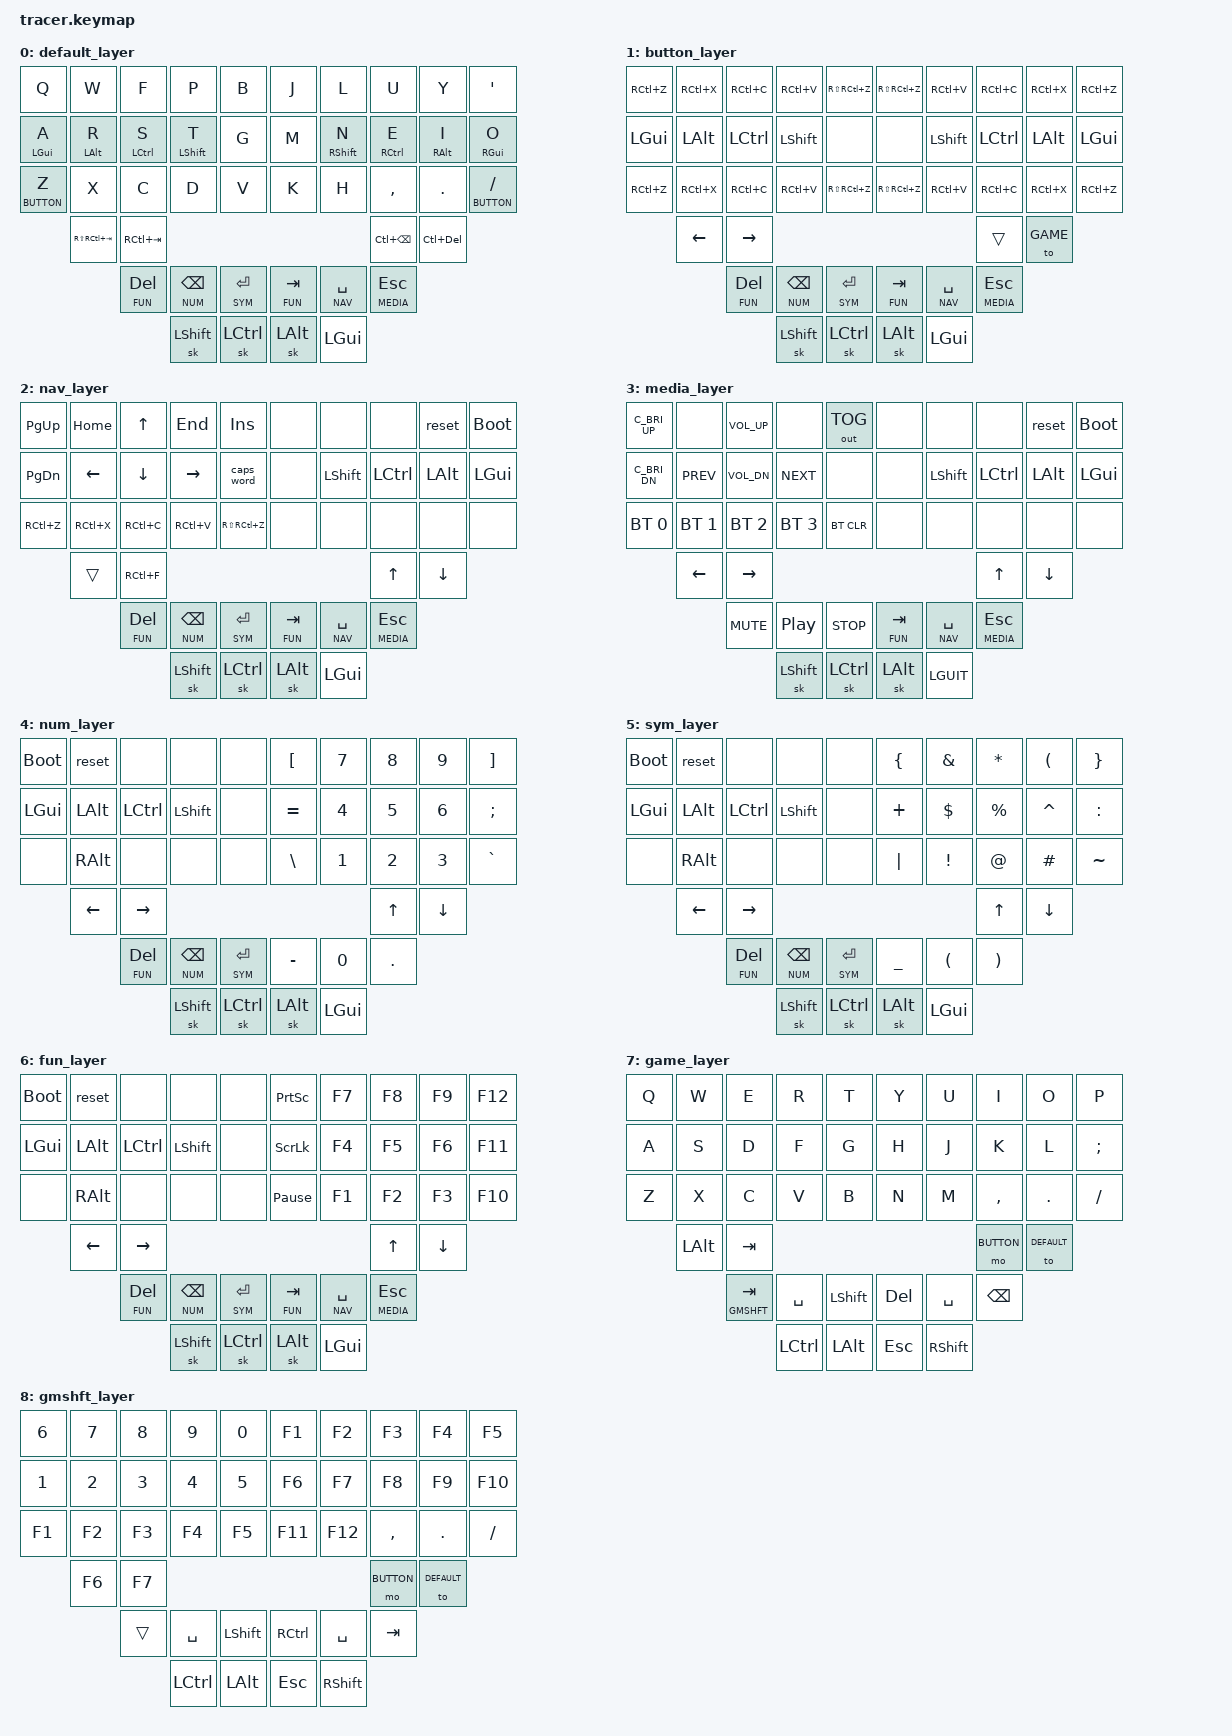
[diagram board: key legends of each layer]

#include <behaviors.dtsi>
#include <dt-bindings/zmk/keys.h>
#include <dt-bindings/zmk/bt.h>
#include <dt-bindings/zmk/outputs.h>

#define DEFAULT 0
#define BUTTON 1
#define NAV    2
#define MEDIA  3
#define NUM    4
#define SYM    5
#define FUN    6
#define GAME   7
#define GMSHFT 8

/ {
	behaviors {
        hm: homerow_mods {
            compatible = "zmk,behavior-hold-tap";
            label = "HOMEROW_MODS";
            #binding-cells = <2>;
            tapping-term-ms = <150>;
            quick-tap-ms = <0>;
            flavor = "tap-preferred";
            bindings = <&kp>,  <&kp>;
        };
    };
	keymap {
		compatible = "zmk,keymap";

		default_layer {
			bindings = <
				&kp Q		&kp W       &kp F         &kp P        &kp B				&kp J   &kp L        &kp U        &kp Y       &kp SQT
				&hm LGUI A	&hm LALT R  &hm LCTRL S   &hm LSHIFT T &kp G				&kp M   &hm RSHFT N  &hm RCTRL E  &hm RALT I  &hm RGUI O
				&lt BUTTON Z &kp X      &kp C         &kp D        &kp V				&kp K   &kp H        &kp COMMA    &kp DOT     &lt BUTTON SLASH
                            &kp RS(RC(TAB))    &kp RC(TAB)                                                   &kp LC(BSPC) &kp LC(DEL)
                                        &lt FUN DEL &lt NUM BSPC  &lt SYM RET           &lt FUN TAB &lt NAV SPACE  &lt MEDIA ESC
                                            	    &sk LSHFT &sk LCTRL 	            &sk LALT  &kp LGUI
			>;

		};

		button_layer {
			bindings = <
				&kp RC(Z)	&kp RC(X)	&kp RC(C)	&kp RC(V)	&kp RS(RC(Z))			&kp RS(RC(Z))	&kp RC(V)	&kp RC(C)	&kp RC(X)	&kp RC(Z)
				&kp LGUI	&kp LALT	&kp LCTRL   &kp LSHFT   &none           		&none      		&kp LSHFT   &kp LCTRL   &kp LALT    &kp LGUI	
				&kp RC(Z)	&kp RC(X)	&kp RC(C)	&kp RC(V)	&kp RS(RC(Z))			&kp RS(RC(Z))	&kp RC(V)	&kp RC(C)	&kp RC(X)	&kp RC(Z) 	 
					        &kp LEFT    &kp RIGHT                                                            &trans     &to GAME
                                        &lt FUN DEL &lt NUM BSPC  &lt SYM RET           &lt FUN TAB &lt NAV SPACE  &lt MEDIA ESC
                                            	    &sk LSHFT &sk LCTRL               &sk LALT  &kp LGUI
			>;    
		};

		nav_layer {
			bindings = <
				&kp PG_UP   &kp HOME      &kp UP        &kp END      &kp INS            &none   &none       &none       &reset		&bootloader
				&kp PG_DN   &kp LEFT      &kp DOWN      &kp RIGHT    &caps_word          &none   &kp LSHFT	&kp LCTRL   &kp LALT    &kp LGUI  
				&kp RC(Z)   &kp RC(X)     &kp RC(C)    &kp RC(V)  &kp RS(RC(Z))         &none   &none       &none       &none  	&none
							&trans       &kp RC(F)                                                        &kp UP      &kp DOWN
							               &lt FUN DEL &lt NUM BSPC  &lt SYM RET        &lt FUN TAB &lt NAV SPACE &lt MEDIA ESC
                                                       &sk LSHFT &sk LCTRL	        &sk LALT  &kp LGUI
																																				
			>;

		};

		media_layer {
			bindings = <
				C_BRI_UP	&none 		&kp C_VOL_UP	&none &out OUT_TOG		            &none		&none	    &none 		&reset		&bootloader	
				C_BRI_DN 	&kp C_PREV  &kp C_VOL_DN	&kp C_NEXT	&none       		    &none		&kp LSHFT	&kp LCTRL	&kp LALT	&kp LGUI
				&bt BT_SEL 0 &bt BT_SEL 1 &bt BT_SEL 2		&bt BT_SEL 3 &bt BT_CLR				&none		&none		&none		&none		&none
							 &kp LEFT    &kp RIGHT                                                          &kp UP       &kp DOWN              	
							            &kp C_MUTE &kp C_PP	&kp C_STOP         		&lt FUN TAB &lt NAV SPACE  &lt MEDIA ESC
										           &sk LSHFT &sk LCTRL		 		&sk LALT  &kp LGUIT
						
	            >;

		};

		num_layer {
			bindings = <
				&bootloader    &reset		&none		&none		&none              &kp LBKT          &kp N7         &kp N8         &kp N9         &kp RBKT
				&kp LGUI       &kp LALT		&kp LCTRL	&kp LSHFT	&none              &kp EQL           &kp N4         &kp N5         &kp N6         &kp SEMI
				&none          &kp RALT		&none   	&none		&none              &kp BSLH          &kp N1         &kp N2         &kp N3         &kp GRAVE  
							   &kp LEFT	 	&kp RIGHT																	&kp UP    	   &kp DOWN
                                			&lt FUN DEL &lt NUM BSPC  &lt SYM RET        &kp MINUS       &kp N0         &kp DOT
								   					    &sk LSHFT &sk LCTRL			     &sk LALT  &kp LGUI
	            >;

		};

        sym_layer {
			bindings = <
				&bootloader		&reset		&none		&none		&none				&kp LBRC		&kp AMPS		&kp ASTRK		&kp LPAR		&kp RBRC
				&kp LGUI		&kp LALT	&kp LCTRL	&kp LSHFT	&none               &kp PLUS		&kp DLLR		&kp PRCNT		&kp CARET		&kp COLON 
				&none			&kp RALT	&none		&none		&none               &kp PIPE		&kp EXCL		&kp AT			&kp HASH		&kp TILDE  
								&kp LEFT	&kp RIGHT																	&kp UP    	    &kp DOWN
                                			&lt FUN DEL &lt NUM BSPC  &lt SYM RET       		&kp UNDER		&kp LPAR		&kp RPAR
								   					    &sk LSHFT &sk LCTRL					    &sk LALT  &kp LGUI 
	            >;

		};

		fun_layer {
			bindings = <
				&bootloader		&reset		&none		&none		&none               &kp PSCRN		&kp F7		&kp F8		&kp F9		&kp F12			
				&kp LGUI		&kp LALT	&kp LCTRL	&kp LSHFT	&none               &kp SLCK		&kp F4		&kp F5		&kp F6		&kp F11
				&none			&kp RALT	&none		&none		&none               &kp PAUSE_BREAK &kp F1		&kp F2		&kp F3		&kp F10   
					            &kp LEFT	&kp RIGHT																&kp UP		&kp DOWN
											&lt FUN DEL &lt NUM BSPC  &lt SYM RET           &lt FUN TAB	&lt NAV SPACE   &lt MEDIA ESC
                                            	    	&sk LSHFT &sk LCTRL	                &sk LALT  &kp LGUI
			>;    
		};

		game_layer {
			bindings = <
			&kp Q &kp W &kp E &kp R &kp T  				        &kp Y &kp U &kp I &kp O &kp P
			&kp A &kp S &kp D &kp F &kp G   					&kp H &kp J &kp K &kp L &kp SEMI
			&kp Z &kp X &kp C &kp V &kp B  					    &kp N &kp M &kp COMMA &kp DOT &kp SLASH
				  &kp LALT &kp TAB								  &mo BUTTON &to DEFAULT
				  		&lt GMSHFT TAB &kp SPACE &kp LSHFT		&kp DEL  &kp SPACE &kp BSPC
						  		&kp LCTRL &kp LALT				&kp ESC &kp RSHFT
			>;

		};

		gmshft_layer {
			bindings = <
			&kp N6 &kp N7 &kp N8 &kp N9 &kp N0 					&kp F1 &kp F2 &kp F3  &kp F4 &kp F5
			&kp N1 &kp N2 &kp N3 &kp N4 &kp N5  					&kp F6 &kp F7 &kp F8 &kp F9 &kp F10
			&kp F1 &kp F2 &kp F3 &kp F4 &kp F5 					&kp F11 &kp F12 &kp COMMA &kp DOT &kp SLASH
				  &kp F6 &kp F7								  &mo BUTTON &to DEFAULT
				  		&trans &kp SPACE &kp LSHFT		&kp RCTRL &kp SPACE &kp TAB
						  		&kp LCTRL &kp LALT		&kp ESC &kp RSHFT
			>;

		};
		
	};
};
